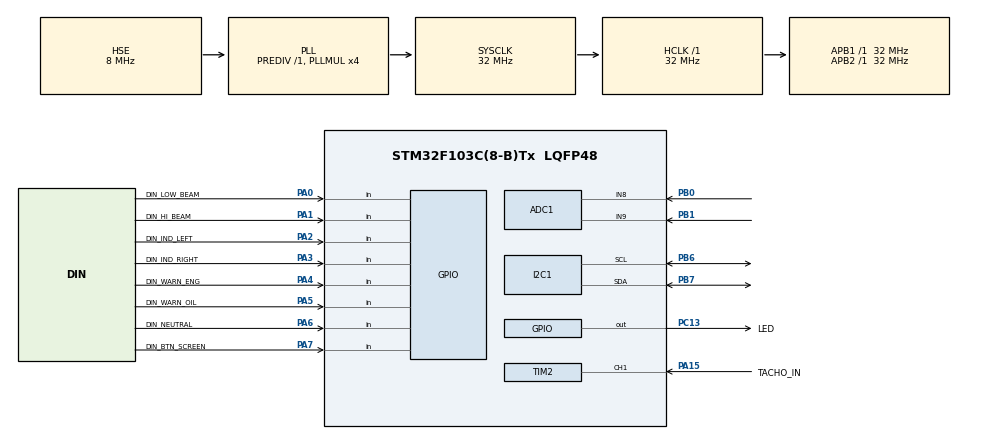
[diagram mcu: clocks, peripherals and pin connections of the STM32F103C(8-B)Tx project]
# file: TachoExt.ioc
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ADC1.Channel-3\#ChannelRegularConversion=ADC_CHANNEL_8
ADC1.Channel-4\#ChannelRegularConversion=ADC_CHANNEL_9
ADC1.NbrOfConversion=2
ADC1.NbrOfConversionFlag=1
ADC1.Rank-3\#ChannelRegularConversion=1
ADC1.Rank-4\#ChannelRegularConversion=2
ADC1.SamplingTime-3\#ChannelRegularConversion=ADC_SAMPLETIME_239CYCLES_5
ADC1.SamplingTime-4\#ChannelRegularConversion=ADC_SAMPLETIME_239CYCLES_5
ADC1.master=1
Dma.ADC1.0.Direction=DMA_PERIPH_TO_MEMORY
Dma.ADC1.0.Instance=DMA1_Channel1
Dma.ADC1.0.MemDataAlignment=DMA_MDATAALIGN_HALFWORD
Dma.ADC1.0.MemInc=DMA_MINC_ENABLE
Dma.ADC1.0.Mode=DMA_NORMAL
Dma.ADC1.0.PeriphDataAlignment=DMA_PDATAALIGN_HALFWORD
Dma.ADC1.0.PeriphInc=DMA_PINC_DISABLE
Dma.ADC1.0.Priority=DMA_PRIORITY_LOW
Dma.Request0=ADC1
I2C1.OwnAddress=56
Mcu.Family=STM32F1
Mcu.Name=STM32F103C(8-B)Tx
Mcu.Package=LQFP48
NVIC.DMA1_Channel1_IRQn=true\:0\:0\:false\:false\:true\:false\:true\:true
NVIC.I2C1_ER_IRQn=true\:0\:0\:false\:false\:false\:true\:false\:true
NVIC.I2C1_EV_IRQn=true\:0\:0\:false\:false\:false\:true\:false\:true
NVIC.PriorityGroup=NVIC_PRIORITYGROUP_4
NVIC.TIM2_IRQn=true\:0\:0\:false\:false\:true\:true\:true\:true
NVIC.TIM3_IRQn=true\:0\:0\:false\:false\:true\:true\:true\:true
PA0-WKUP.GPIO_Label=DIN_LOW_BEAM
PA0-WKUP.GPIO_PuPd=GPIO_PULLUP
PA0-WKUP.Signal=GPIO_Input
PA1.GPIO_Label=DIN_HI_BEAM
PA1.GPIO_PuPd=GPIO_PULLUP
PA1.Signal=GPIO_Input
PA13.Mode=Serial_Wire
PA13.Signal=SYS_JTMS-SWDIO
PA14.Mode=Serial_Wire
PA14.Signal=SYS_JTCK-SWCLK
PA15.GPIO_Label=TACHO_IN
PA15.GPIO_PuPd=GPIO_PULLUP
PA15.Signal=S_TIM2_CH1_ETR
PA2.GPIO_Label=DIN_IND_LEFT
PA2.GPIO_PuPd=GPIO_PULLUP
PA2.Signal=GPIO_Input
PA3.GPIO_Label=DIN_IND_RIGHT
PA3.GPIO_PuPd=GPIO_PULLUP
PA3.Signal=GPIO_Input
PA4.GPIO_Label=DIN_WARN_ENG
PA4.GPIO_PuPd=GPIO_PULLUP
PA4.Signal=GPIO_Input
PA5.GPIO_Label=DIN_WARN_OIL
PA5.GPIO_PuPd=GPIO_PULLUP
PA5.Signal=GPIO_Input
PA6.GPIO_Label=DIN_NEUTRAL
PA6.GPIO_PuPd=GPIO_PULLUP
PA6.Signal=GPIO_Input
PA7.GPIO_Label=DIN_BTN_SCREEN
PA7.GPIO_PuPd=GPIO_PULLUP
PA7.Signal=GPIO_Input
PB0.Signal=ADCx_IN8
PB1.Signal=ADCx_IN9
PB6.Mode=I2C
PB6.Signal=I2C1_SCL
PB7.Mode=I2C
PB7.Signal=I2C1_SDA
PC13-TAMPER-RTC.GPIO_Label=LED
PC13-TAMPER-RTC.Signal=GPIO_Output
PD0-OSC_IN.Mode=HSE-External-Oscillator
PD0-OSC_IN.Signal=RCC_OSC_IN
PD1-OSC_OUT.Mode=HSE-External-Oscillator
PD1-OSC_OUT.Signal=RCC_OSC_OUT
ProjectManager.HeapSize=0x200
ProjectManager.StackSize=0x400
ProjectManager.TargetToolchain=Makefile
RCC.ADCPresc=RCC_ADCPCLK2_DIV8
RCC.AHBFreq_Value=32000000
RCC.APB1Freq_Value=32000000
RCC.APB1TimFreq_Value=32000000
RCC.APB2Freq_Value=32000000
RCC.APB2TimFreq_Value=32000000
RCC.HCLKFreq_Value=32000000
RCC.PLLMUL=RCC_PLL_MUL4
RCC.PLLSourceVirtual=RCC_PLLSOURCE_HSE
RCC.SYSCLKFreq_VALUE=32000000
RCC.SYSCLKSource=RCC_SYSCLKSOURCE_PLLCLK
RCC.USBFreq_Value=32000000
SH.ADCx_IN8.0=ADC1_IN8,IN8
SH.ADCx_IN9.0=ADC1_IN9,IN9
SH.S_TIM2_CH1_ETR.0=TIM2_CH1,Input_Capture1_from_TI1
TIM2.Channel-Input_Capture1_from_TI1=TIM_CHANNEL_1
TIM2.ICFilter_CH1=15
TIM2.ICPolarity_CH1=TIM_INPUTCHANNELPOLARITY_FALLING
TIM2.TIM_MasterSlaveMode=TIM_MASTERSLAVEMODE_ENABLE
TIM3.Channel-Output\ Compare1\ No\ Output=TIM_CHANNEL_1
VP_TIM2_VS_ClockSourceINT.Mode=Internal
VP_TIM3_VS_ClockSourceITR.Mode=TriggerSource_ITR1
VP_TIM3_VS_ControllerModeClock.Mode=Clock Mode
VP_TIM3_VS_no_output1.Mode=Output Compare1 No Output
board=custom

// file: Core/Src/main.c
/* USER CODE BEGIN Header */
/**
  ******************************************************************************
  * @file           : main.c
  * @brief          : Main program body
  ******************************************************************************
  * @attention
  *
  * Copyright (c) 2026 STMicroelectronics.
  * All rights reserved.
  *
  * This software is licensed under terms that can be found in the LICENSE file
  * in the root directory of this software component.
  * If no LICENSE file comes with this software, it is provided AS-IS.
  *
  ******************************************************************************
  */
/* USER CODE END Header */
#include "main.h"

/* USER CODE BEGIN Includes */
#include "i2c_slave.h"
/* USER CODE END Includes */

ADC_HandleTypeDef hadc1;
DMA_HandleTypeDef hdma_adc1;

I2C_HandleTypeDef hi2c1;

TIM_HandleTypeDef htim2;
TIM_HandleTypeDef htim3;

void SystemClock_Config(void);
static void MX_GPIO_Init(void);
static void MX_DMA_Init(void);
static void MX_ADC1_Init(void);
static void MX_TIM2_Init(void);
static void MX_TIM3_Init(void);
static void MX_I2C1_Init(void);

int main(void)
{

  /* MCU Configuration--------------------------------------------------------*/

  /* Reset of all peripherals, Initializes the Flash interface and the Systick. */
  HAL_Init();

  /* Configure the system clock */
  SystemClock_Config();

  /* Initialize all configured peripherals */
  MX_GPIO_Init();
  MX_DMA_Init();
  MX_ADC1_Init();
  MX_TIM2_Init();
  MX_TIM3_Init();
  MX_I2C1_Init();
  /* USER CODE BEGIN 2 */
  i2c_slave_init(&hi2c1);
  /* USER CODE END 2 */

  /* Infinite loop */
  /* USER CODE BEGIN WHILE */
  while (1)
  {
    HAL_GPIO_TogglePin(LED_GPIO_Port, LED_Pin);
    HAL_Delay(500);
    /* USER CODE END WHILE */

  }
}

void SystemClock_Config(void)
{
  RCC_OscInitTypeDef RCC_OscInitStruct = {0};
  RCC_ClkInitTypeDef RCC_ClkInitStruct = {0};
  RCC_PeriphCLKInitTypeDef PeriphClkInit = {0};

  /** Initializes the RCC Oscillators according to the specified parameters
  * in the RCC_OscInitTypeDef structure.
  */
  RCC_OscInitStruct.OscillatorType = RCC_OSCILLATORTYPE_HSE;
  RCC_OscInitStruct.HSEState = RCC_HSE_ON;
  RCC_OscInitStruct.HSEPredivValue = RCC_HSE_PREDIV_DIV1;
  RCC_OscInitStruct.HSIState = RCC_HSI_ON;
  RCC_OscInitStruct.PLL.PLLState = RCC_PLL_ON;
  RCC_OscInitStruct.PLL.PLLSource = RCC_PLLSOURCE_HSE;
  RCC_OscInitStruct.PLL.PLLMUL = RCC_PLL_MUL4;
  if (HAL_RCC_OscConfig(&RCC_OscInitStruct) != HAL_OK)
  {
    Error_Handler();
  }

  /** Initializes the CPU, AHB and APB buses clocks
  */
  RCC_ClkInitStruct.ClockType = RCC_CLOCKTYPE_HCLK|RCC_CLOCKTYPE_SYSCLK
                              |RCC_CLOCKTYPE_PCLK1|RCC_CLOCKTYPE_PCLK2;
  RCC_ClkInitStruct.SYSCLKSource = RCC_SYSCLKSOURCE_PLLCLK;
  RCC_ClkInitStruct.AHBCLKDivider = RCC_SYSCLK_DIV1;
  RCC_ClkInitStruct.APB1CLKDivider = RCC_HCLK_DIV1;
  RCC_ClkInitStruct.APB2CLKDivider = RCC_HCLK_DIV1;

  if (HAL_RCC_ClockConfig(&RCC_ClkInitStruct, FLASH_LATENCY_1) != HAL_OK)
  {
    Error_Handler();
  }
  PeriphClkInit.PeriphClockSelection = RCC_PERIPHCLK_ADC;
  PeriphClkInit.AdcClockSelection = RCC_ADCPCLK2_DIV8;
  if (HAL_RCCEx_PeriphCLKConfig(&PeriphClkInit) != HAL_OK)
  {
    Error_Handler();
  }
}

static void MX_ADC1_Init(void)
{

  ADC_ChannelConfTypeDef sConfig = {0};

  /** Common config
  */
  hadc1.Instance = ADC1;
  hadc1.Init.ScanConvMode = ADC_SCAN_ENABLE;
  hadc1.Init.ContinuousConvMode = DISABLE;
  hadc1.Init.DiscontinuousConvMode = DISABLE;
  hadc1.Init.ExternalTrigConv = ADC_SOFTWARE_START;
  hadc1.Init.DataAlign = ADC_DATAALIGN_RIGHT;
  hadc1.Init.NbrOfConversion = 2;
  if (HAL_ADC_Init(&hadc1) != HAL_OK)
  {
    Error_Handler();
  }

  /** Configure Regular Channel
  */
  sConfig.Channel = ADC_CHANNEL_8;
  sConfig.Rank = ADC_REGULAR_RANK_1;
  sConfig.SamplingTime = ADC_SAMPLETIME_239CYCLES_5;
  if (HAL_ADC_ConfigChannel(&hadc1, &sConfig) != HAL_OK)
  {
    Error_Handler();
  }

  /** Configure Regular Channel
  */
  sConfig.Channel = ADC_CHANNEL_9;
  sConfig.Rank = ADC_REGULAR_RANK_2;
  if (HAL_ADC_ConfigChannel(&hadc1, &sConfig) != HAL_OK)
  {
    Error_Handler();
  }

}

static void MX_I2C1_Init(void)
{

  hi2c1.Instance = I2C1;
  hi2c1.Init.ClockSpeed = 100000;
  hi2c1.Init.DutyCycle = I2C_DUTYCYCLE_2;
  hi2c1.Init.OwnAddress1 = 112;
  hi2c1.Init.AddressingMode = I2C_ADDRESSINGMODE_7BIT;
  hi2c1.Init.DualAddressMode = I2C_DUALADDRESS_DISABLE;
  hi2c1.Init.OwnAddress2 = 0;
  hi2c1.Init.GeneralCallMode = I2C_GENERALCALL_DISABLE;
  hi2c1.Init.NoStretchMode = I2C_NOSTRETCH_DISABLE;
  if (HAL_I2C_Init(&hi2c1) != HAL_OK)
  {
    Error_Handler();
  }

}

static void MX_TIM2_Init(void)
{

  TIM_ClockConfigTypeDef sClockSourceConfig = {0};
  TIM_MasterConfigTypeDef sMasterConfig = {0};
  TIM_IC_InitTypeDef sConfigIC = {0};

  htim2.Instance = TIM2;
  htim2.Init.Prescaler = 0;
  htim2.Init.CounterMode = TIM_COUNTERMODE_UP;
  htim2.Init.Period = 65535;
  htim2.Init.ClockDivision = TIM_CLOCKDIVISION_DIV1;
  htim2.Init.AutoReloadPreload = TIM_AUTORELOAD_PRELOAD_DISABLE;
  if (HAL_TIM_Base_Init(&htim2) != HAL_OK)
  {
    Error_Handler();
  }
  sClockSourceConfig.ClockSource = TIM_CLOCKSOURCE_INTERNAL;
  if (HAL_TIM_ConfigClockSource(&htim2, &sClockSourceConfig) != HAL_OK)
  {
    Error_Handler();
  }
  if (HAL_TIM_IC_Init(&htim2) != HAL_OK)
  {
    Error_Handler();
  }
  sMasterConfig.MasterOutputTrigger = TIM_TRGO_RESET;
  sMasterConfig.MasterSlaveMode = TIM_MASTERSLAVEMODE_ENABLE;
  if (HAL_TIMEx_MasterConfigSynchronization(&htim2, &sMasterConfig) != HAL_OK)
  {
    Error_Handler();
  }
  sConfigIC.ICPolarity = TIM_INPUTCHANNELPOLARITY_FALLING;
  sConfigIC.ICSelection = TIM_ICSELECTION_DIRECTTI;
  sConfigIC.ICPrescaler = TIM_ICPSC_DIV1;
  sConfigIC.ICFilter = 15;
  if (HAL_TIM_IC_ConfigChannel(&htim2, &sConfigIC, TIM_CHANNEL_1) != HAL_OK)
  {
    Error_Handler();
  }

}

static void MX_TIM3_Init(void)
{

  TIM_SlaveConfigTypeDef sSlaveConfig = {0};
  TIM_MasterConfigTypeDef sMasterConfig = {0};
  TIM_OC_InitTypeDef sConfigOC = {0};

  htim3.Instance = TIM3;
  htim3.Init.Prescaler = 0;
  htim3.Init.CounterMode = TIM_COUNTERMODE_UP;
  htim3.Init.Period = 65535;
  htim3.Init.ClockDivision = TIM_CLOCKDIVISION_DIV1;
  htim3.Init.AutoReloadPreload = TIM_AUTORELOAD_PRELOAD_DISABLE;
  if (HAL_TIM_Base_Init(&htim3) != HAL_OK)
  {
    Error_Handler();
  }
  if (HAL_TIM_OC_Init(&htim3) != HAL_OK)
  {
    Error_Handler();
  }
  sSlaveConfig.SlaveMode = TIM_SLAVEMODE_EXTERNAL1;
  sSlaveConfig.InputTrigger = TIM_TS_ITR1;
  if (HAL_TIM_SlaveConfigSynchro(&htim3, &sSlaveConfig) != HAL_OK)
  {
    Error_Handler();
  }
  sMasterConfig.MasterOutputTrigger = TIM_TRGO_RESET;
  sMasterConfig.MasterSlaveMode = TIM_MASTERSLAVEMODE_DISABLE;
  if (HAL_TIMEx_MasterConfigSynchronization(&htim3, &sMasterConfig) != HAL_OK)
  {
    Error_Handler();
  }
  sConfigOC.OCMode = TIM_OCMODE_TIMING;
  sConfigOC.Pulse = 0;
  sConfigOC.OCPolarity = TIM_OCPOLARITY_HIGH;
  sConfigOC.OCFastMode = TIM_OCFAST_DISABLE;
  if (HAL_TIM_OC_ConfigChannel(&htim3, &sConfigOC, TIM_CHANNEL_1) != HAL_OK)
  {
    Error_Handler();
  }

}

static void MX_DMA_Init(void)
{

  /* DMA controller clock enable */
  __HAL_RCC_DMA1_CLK_ENABLE();

  /* DMA interrupt init */
  /* DMA1_Channel1_IRQn interrupt configuration */
  HAL_NVIC_SetPriority(DMA1_Channel1_IRQn, 0, 0);
  HAL_NVIC_EnableIRQ(DMA1_Channel1_IRQn);

}

static void MX_GPIO_Init(void)
{
  GPIO_InitTypeDef GPIO_InitStruct = {0};

  /* GPIO Ports Clock Enable */
  __HAL_RCC_GPIOC_CLK_ENABLE();
  __HAL_RCC_GPIOD_CLK_ENABLE();
  __HAL_RCC_GPIOA_CLK_ENABLE();
  __HAL_RCC_GPIOB_CLK_ENABLE();

  /*Configure GPIO pin Output Level */
  HAL_GPIO_WritePin(LED_GPIO_Port, LED_Pin, GPIO_PIN_RESET);

  /*Configure GPIO pin : LED_Pin */
  GPIO_InitStruct.Pin = LED_Pin;
  GPIO_InitStruct.Mode = GPIO_MODE_OUTPUT_PP;
  GPIO_InitStruct.Pull = GPIO_NOPULL;
  GPIO_InitStruct.Speed = GPIO_SPEED_FREQ_LOW;
  HAL_GPIO_Init(LED_GPIO_Port, &GPIO_InitStruct);

  /*Configure GPIO pins : PC14 PC15 */
  GPIO_InitStruct.Pin = GPIO_PIN_14|GPIO_PIN_15;
  GPIO_InitStruct.Mode = GPIO_MODE_ANALOG;
  HAL_GPIO_Init(GPIOC, &GPIO_InitStruct);

  /*Configure GPIO pins : DIN_LOW_BEAM_Pin DIN_HI_BEAM_Pin DIN_IND_LEFT_Pin DIN_IND_RIGHT_Pin
                           DIN_WARN_ENG_Pin DIN_WARN_OIL_Pin DIN_NEUTRAL_Pin DIN_BTN_SCREEN_Pin */
  GPIO_InitStruct.Pin = DIN_LOW_BEAM_Pin|DIN_HI_BEAM_Pin|DIN_IND_LEFT_Pin|DIN_IND_RIGHT_Pin
                          |DIN_WARN_ENG_Pin|DIN_WARN_OIL_Pin|DIN_NEUTRAL_Pin|DIN_BTN_SCREEN_Pin;
  GPIO_InitStruct.Mode = GPIO_MODE_INPUT;
  GPIO_InitStruct.Pull = GPIO_PULLUP;
  HAL_GPIO_Init(GPIOA, &GPIO_InitStruct);

  /*Configure GPIO pins : PB2 PB10 PB11 PB12
                           PB13 PB14 PB15 PB3
                           PB4 PB5 PB8 PB9 */
  GPIO_InitStruct.Pin = GPIO_PIN_2|GPIO_PIN_10|GPIO_PIN_11|GPIO_PIN_12
                          |GPIO_PIN_13|GPIO_PIN_14|GPIO_PIN_15|GPIO_PIN_3
                          |GPIO_PIN_4|GPIO_PIN_5|GPIO_PIN_8|GPIO_PIN_9;
  GPIO_InitStruct.Mode = GPIO_MODE_ANALOG;
  HAL_GPIO_Init(GPIOB, &GPIO_InitStruct);

  /*Configure GPIO pins : PA8 PA9 PA10 PA11
                           PA12 */
  GPIO_InitStruct.Pin = GPIO_PIN_8|GPIO_PIN_9|GPIO_PIN_10|GPIO_PIN_11
                          |GPIO_PIN_12;
  GPIO_InitStruct.Mode = GPIO_MODE_ANALOG;
  HAL_GPIO_Init(GPIOA, &GPIO_InitStruct);

}

void Error_Handler(void)
{
  __disable_irq();
  while (1)
  {
  }
}
